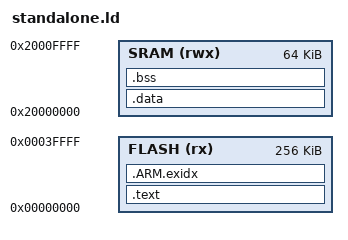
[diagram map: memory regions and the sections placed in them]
MEMORY
{
    FLASH (rx) : ORIGIN = 0x00000000, LENGTH = 256K
    SRAM (rwx) : ORIGIN = 0x20000000, LENGTH = 64K
}

SECTIONS
{
    .text :
    {
        KEEP(*(.isr_vector))
        *(.text*)
        *(.rodata*)
        *(.ARM.exidx)
        _etext = .;
    } > FLASH

    /* Place .ARM.exidx after .data */
    .data : AT (ADDR(.text) + SIZEOF(.text))
    {
        _data = .;
        *(vtable)
        *(.data*)
        _edata = .;
    } > SRAM

    /* Define .ARM.exidx section */
    .ARM.exidx :
    {
        *(.ARM.exidx*)
    } > FLASH

    .bss :
    {
        _bss = .;
        *(.bss*)
        *(COMMON)
        _ebss = .;
    } > SRAM
}
